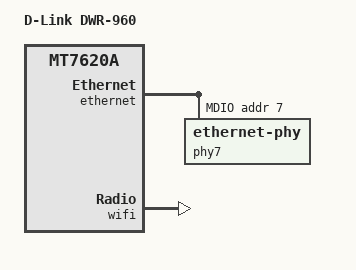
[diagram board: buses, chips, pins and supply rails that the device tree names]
// SPDX-License-Identifier: GPL-2.0-or-later OR MIT

#include "mt7620a_dlink_dwr-96x.dtsi"

/ {
	compatible = "dlink,dwr-960", "ralink,mt7620a-soc";
	model = "D-Link DWR-960";
};

&ethernet {
	pinctrl-names = "default";
	pinctrl-0 = <&rgmii2_pins &mdio_pins>;

	mediatek,portmap = "wllll";

	port@5 {
		status = "okay";
		phy-mode = "rgmii-txid";
		phy-handle = <&phy7>;
	};

	mdio-bus {
		status = "okay";

		phy7: ethernet-phy@7 {
			reg = <7>;
			phy-mode = "rgmii-id";
		};
	};
};

&wifi {
	mediatek,mtd-eeprom = <&config 0xe08e>;
};
